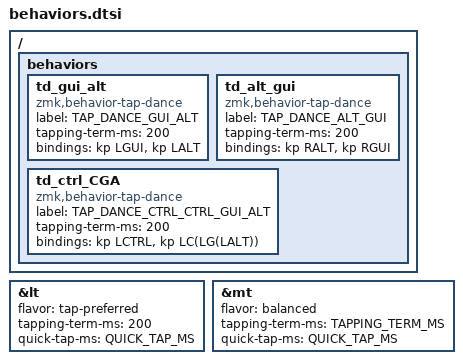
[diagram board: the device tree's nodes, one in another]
/**
 *	https://zmk.dev/docs/config/behaviors
 */

&lt {
    flavor          = "tap-preferred";
    tapping-term-ms = <200>;
    quick-tap-ms    = <QUICK_TAP_MS>;
};

&mt {
	flavor = "balanced";
	tapping-term-ms = <TAPPING_TERM_MS>;
	quick-tap-ms = <QUICK_TAP_MS>;
};

/ {
	behaviors {

        td_gui_alt: td_gui_alt {
            compatible = "zmk,behavior-tap-dance";
            label = "TAP_DANCE_GUI_ALT";
            #binding-cells = <0>;
            tapping-term-ms = <200>;
            bindings = <&kp LGUI>, <&kp LALT>;
        };

        td_alt_gui: td_alt_gui {
            compatible = "zmk,behavior-tap-dance";
            label = "TAP_DANCE_ALT_GUI";
            #binding-cells = <0>;
            tapping-term-ms = <200>;
            bindings = <&kp RALT>, <&kp RGUI>;
        };

		td_ctrl_CGA: td_ctrl_CGA {
            compatible = "zmk,behavior-tap-dance";
            label = "TAP_DANCE_CTRL_CTRL_GUI_ALT";
            #binding-cells = <0>;
            tapping-term-ms = <200>;
            bindings = <&kp LCTRL>, <&kp LC(LG(LALT))>;
        };

    };
};
